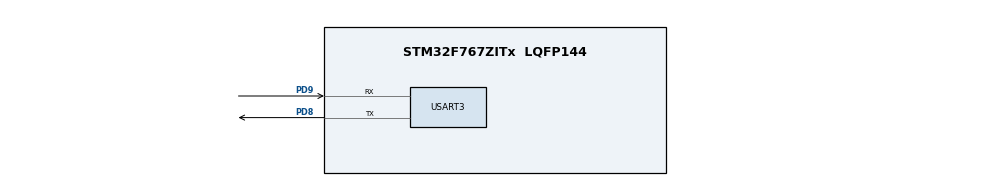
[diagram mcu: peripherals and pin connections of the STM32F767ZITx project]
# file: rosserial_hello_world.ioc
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Dma.Request0=USART3_RX
Dma.Request1=USART3_TX
Dma.USART3_RX.0.Direction=DMA_PERIPH_TO_MEMORY
Dma.USART3_RX.0.FIFOMode=DMA_FIFOMODE_DISABLE
Dma.USART3_RX.0.Instance=DMA1_Stream1
Dma.USART3_RX.0.MemDataAlignment=DMA_MDATAALIGN_BYTE
Dma.USART3_RX.0.MemInc=DMA_MINC_ENABLE
Dma.USART3_RX.0.Mode=DMA_NORMAL
Dma.USART3_RX.0.PeriphDataAlignment=DMA_PDATAALIGN_BYTE
Dma.USART3_RX.0.PeriphInc=DMA_PINC_DISABLE
Dma.USART3_RX.0.Priority=DMA_PRIORITY_LOW
Dma.USART3_TX.1.Direction=DMA_MEMORY_TO_PERIPH
Dma.USART3_TX.1.FIFOMode=DMA_FIFOMODE_DISABLE
Dma.USART3_TX.1.Instance=DMA1_Stream3
Dma.USART3_TX.1.MemDataAlignment=DMA_MDATAALIGN_BYTE
Dma.USART3_TX.1.MemInc=DMA_MINC_ENABLE
Dma.USART3_TX.1.Mode=DMA_NORMAL
Dma.USART3_TX.1.PeriphDataAlignment=DMA_PDATAALIGN_BYTE
Dma.USART3_TX.1.PeriphInc=DMA_PINC_DISABLE
Dma.USART3_TX.1.Priority=DMA_PRIORITY_LOW
Mcu.Family=STM32F7
Mcu.Name=STM32F767ZITx
Mcu.Package=LQFP144
NVIC.DMA1_Stream1_IRQn=true\:0\:0\:false\:false\:true\:false\:true
NVIC.DMA1_Stream3_IRQn=true\:0\:0\:false\:false\:true\:false\:true
NVIC.PriorityGroup=NVIC_PRIORITYGROUP_4
NVIC.USART3_IRQn=true\:0\:0\:false\:false\:true\:true\:true
PD8.Mode=Asynchronous
PD8.Signal=USART3_TX
PD9.Mode=Asynchronous
PD9.Signal=USART3_RX
ProjectManager.HeapSize=0x200
ProjectManager.StackSize=0x400
ProjectManager.TargetToolchain=STM32CubeIDE
RCC.HSE_VALUE=25000000
RCC.HSI_VALUE=16000000
RCC.LSE_VALUE=32768
RCC.USBFreq_Value=96000000
RCC.VCOOutputFreq_Value=192000000
USART3.VirtualMode-Asynchronous=VM_ASYNC
VP_TIM2_VS_ClockSourceINT.Mode=Internal
board=custom

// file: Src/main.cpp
/* USER CODE BEGIN Header */
/**
 ******************************************************************************
 * @file           : main.c
 * @brief          : Main program body
 ******************************************************************************
 * @attention
 *
 * <h2><center>&copy; Copyright (c) 2019 STMicroelectronics.
 * All rights reserved.</center></h2>
 *
 * This software component is licensed by ST under BSD 3-Clause license,
 * the "License"; You may not use this file except in compliance with the
 * License. You may obtain a copy of the License at:
 *                        opensource.org/licenses/BSD-3-Clause
 *
 ******************************************************************************
 */
/* USER CODE END Header */

#include "main.h"

/* USER CODE BEGIN Includes */
#include <std_msgs/String.h>
#include <ros.h>

/* USER CODE END Includes */

TIM_HandleTypeDef htim2;

UART_HandleTypeDef huart3;
DMA_HandleTypeDef hdma_usart3_rx;
DMA_HandleTypeDef hdma_usart3_tx;

void SystemClock_Config(void);
static void MX_GPIO_Init(void);
static void MX_DMA_Init(void);
static void MX_TIM2_Init(void);
static void MX_USART3_UART_Init(void);

int main(void) {

	/* MCU Configuration--------------------------------------------------------*/

	/* Reset of all peripherals, Initializes the Flash interface and the Systick. */
	HAL_Init();

	/* Configure the system clock */
	SystemClock_Config();

	/* Initialize all configured peripherals */
	MX_GPIO_Init();
	MX_DMA_Init();
	MX_TIM2_Init();
	MX_USART3_UART_Init();
	/* USER CODE BEGIN 2 */
	ros::NodeHandle nh;

	std_msgs::String str_msg;
	ros::Publisher chatter("chatter", &str_msg);
	char hello[] = "Hello world!";

	nh.initNode();
	nh.advertise(chatter);

	/* USER CODE END 2 */

	/* Infinite loop */
	/* USER CODE BEGIN WHILE */
	while (1) {

		str_msg.data = hello;
		chatter.publish(&str_msg);
		nh.spinOnce();

		//HAL_UART_Transmit(&huart3, (uint8_t*)hello, strlen(hello), 100);

		HAL_Delay(1000);

		/* USER CODE END WHILE */

	}
}

void SystemClock_Config(void) {
	RCC_OscInitTypeDef RCC_OscInitStruct = { 0 };
	RCC_ClkInitTypeDef RCC_ClkInitStruct = { 0 };
	RCC_PeriphCLKInitTypeDef PeriphClkInitStruct = { 0 };

	/** Configure the main internal regulator output voltage
	 */
	__HAL_RCC_PWR_CLK_ENABLE()
	;
	__HAL_PWR_VOLTAGESCALING_CONFIG(PWR_REGULATOR_VOLTAGE_SCALE3);
	/** Initializes the CPU, AHB and APB busses clocks
	 */
	RCC_OscInitStruct.OscillatorType = RCC_OSCILLATORTYPE_HSI;
	RCC_OscInitStruct.HSIState = RCC_HSI_ON;
	RCC_OscInitStruct.HSICalibrationValue = RCC_HSICALIBRATION_DEFAULT;
	RCC_OscInitStruct.PLL.PLLState = RCC_PLL_NONE;
	if (HAL_RCC_OscConfig(&RCC_OscInitStruct) != HAL_OK) {
		Error_Handler();
	}
	/** Initializes the CPU, AHB and APB busses clocks
	 */
	RCC_ClkInitStruct.ClockType = RCC_CLOCKTYPE_HCLK | RCC_CLOCKTYPE_SYSCLK
			| RCC_CLOCKTYPE_PCLK1 | RCC_CLOCKTYPE_PCLK2;
	RCC_ClkInitStruct.SYSCLKSource = RCC_SYSCLKSOURCE_HSI;
	RCC_ClkInitStruct.AHBCLKDivider = RCC_SYSCLK_DIV1;
	RCC_ClkInitStruct.APB1CLKDivider = RCC_HCLK_DIV1;
	RCC_ClkInitStruct.APB2CLKDivider = RCC_HCLK_DIV1;

	if (HAL_RCC_ClockConfig(&RCC_ClkInitStruct, FLASH_LATENCY_0) != HAL_OK) {
		Error_Handler();
	}
	PeriphClkInitStruct.PeriphClockSelection = RCC_PERIPHCLK_USART3;
	PeriphClkInitStruct.Usart3ClockSelection = RCC_USART3CLKSOURCE_PCLK1;
	if (HAL_RCCEx_PeriphCLKConfig(&PeriphClkInitStruct) != HAL_OK) {
		Error_Handler();
	}
}

static void MX_TIM2_Init(void) {

	TIM_ClockConfigTypeDef sClockSourceConfig = { 0 };
	TIM_MasterConfigTypeDef sMasterConfig = { 0 };

	htim2.Instance = TIM2;
	htim2.Init.Prescaler = 0;
	htim2.Init.CounterMode = TIM_COUNTERMODE_UP;
	htim2.Init.Period = 0;
	htim2.Init.ClockDivision = TIM_CLOCKDIVISION_DIV1;
	htim2.Init.AutoReloadPreload = TIM_AUTORELOAD_PRELOAD_DISABLE;
	if (HAL_TIM_Base_Init(&htim2) != HAL_OK) {
		Error_Handler();
	}
	sClockSourceConfig.ClockSource = TIM_CLOCKSOURCE_INTERNAL;
	if (HAL_TIM_ConfigClockSource(&htim2, &sClockSourceConfig) != HAL_OK) {
		Error_Handler();
	}
	sMasterConfig.MasterOutputTrigger = TIM_TRGO_RESET;
	sMasterConfig.MasterSlaveMode = TIM_MASTERSLAVEMODE_DISABLE;
	if (HAL_TIMEx_MasterConfigSynchronization(&htim2, &sMasterConfig)
			!= HAL_OK) {
		Error_Handler();
	}

}

static void MX_USART3_UART_Init(void) {

	huart3.Instance = USART3;
	huart3.Init.BaudRate = 115200;
	huart3.Init.WordLength = UART_WORDLENGTH_8B;
	huart3.Init.StopBits = UART_STOPBITS_1;
	huart3.Init.Parity = UART_PARITY_NONE;
	huart3.Init.Mode = UART_MODE_TX_RX;
	huart3.Init.HwFlowCtl = UART_HWCONTROL_NONE;
	huart3.Init.OverSampling = UART_OVERSAMPLING_16;
	huart3.Init.OneBitSampling = UART_ONE_BIT_SAMPLE_DISABLE;
	huart3.AdvancedInit.AdvFeatureInit = UART_ADVFEATURE_NO_INIT;
	if (HAL_UART_Init(&huart3) != HAL_OK) {
		Error_Handler();
	}

}

static void MX_DMA_Init(void) {

	/* DMA controller clock enable */
	__HAL_RCC_DMA1_CLK_ENABLE()
	;

	/* DMA interrupt init */
	/* DMA1_Stream1_IRQn interrupt configuration */
	HAL_NVIC_SetPriority(DMA1_Stream1_IRQn, 0, 0);
	HAL_NVIC_EnableIRQ(DMA1_Stream1_IRQn);
	/* DMA1_Stream3_IRQn interrupt configuration */
	HAL_NVIC_SetPriority(DMA1_Stream3_IRQn, 0, 0);
	HAL_NVIC_EnableIRQ(DMA1_Stream3_IRQn);

}

static void MX_GPIO_Init(void) {

	/* GPIO Ports Clock Enable */
	__HAL_RCC_GPIOD_CLK_ENABLE()
	;

}

void Error_Handler(void) {
}

/************************ (C) COPYRIGHT STMicroelectronics *****END OF FILE****/
